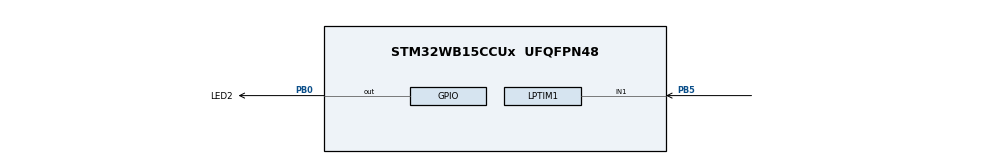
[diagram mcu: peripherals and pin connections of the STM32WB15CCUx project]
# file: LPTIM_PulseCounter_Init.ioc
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LPTIM1.TriggerSource=LPTIM_TRIGSOURCE_SOFTWARE
LPTIM1.ULPClockPolarity=LPTIM_CLOCKPOLARITY_RISING
LPTIM1.ULPClockSampleTime=LPTIM_CLOCKSAMPLETIME_DIRECTTRANSITION
LPTIM1.UpdateMode=LPTIM_UPDATE_IMMEDIATE
Mcu.Family=STM32WB
Mcu.Name=STM32WB15CCUx
Mcu.Package=UFQFPN48
NVIC.LPTIM1_IRQn=true\:0\:0\:false\:false\:true\:true\:true
NVIC.PriorityGroup=NVIC_PRIORITYGROUP_4
PB0.GPIO_Label=LED2
PB0.Signal=GPIO_Output
PB5.GPIO_PuPd=GPIO_PULLDOWN
PB5.GPIO_Speed=GPIO_SPEED_FREQ_HIGH
PB5.Mode=Counts_external_clock_with_synchro_01_occur1
PB5.Signal=LPTIM1_IN1
ProjectManager.HeapSize=0x200
ProjectManager.StackSize=0x400
ProjectManager.TargetToolchain=EWARM V8
RCC.AHB2CLKDivider=RCC_SYSCLK_DIV2
RCC.AHBFreq_Value=64000000
RCC.APB1Freq_Value=64000000
RCC.APB1TimFreq_Value=64000000
RCC.APB2Freq_Value=64000000
RCC.APB2TimFreq_Value=64000000
RCC.APB3Freq_Value=16000000
RCC.CortexFreq_Value=64000000
RCC.HCLKFreq_Value=64000000
RCC.HSE_VALUE=8000000
RCC.HSI_VALUE=16000000
RCC.LPTIM1CLockSelection=RCC_LPTIM1CLKSOURCE_LSI
RCC.LSE_VALUE=32768
RCC.PLLN=32
RCC.SYSCLKFreq_VALUE=64000000
RCC.SYSCLKSource=RCC_SYSCLKSOURCE_PLLCLK
RCC.VCOOutputFreq_Value=128000000
board=custom

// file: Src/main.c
/* USER CODE BEGIN Header */
/**
  ******************************************************************************
  * @file    Examples_LL/LPTIM/LPTIM_PulseCounter_Init/Src/main.c
  * @author  MCD Application Team
  * @brief   This example describes how to use the LPTIM in counter mode
  *          using the STM32WBxx LPTIM LL API.
  *          Peripheral initialization done using LL initialization function.
  ******************************************************************************
  * @attention
  *
  * <h2><center>&copy; Copyright (c) 2019 STMicroelectronics.
  * All rights reserved.</center></h2>
  *
  * This software component is licensed by ST under BSD 3-Clause license,
  * the "License"; You may not use this file except in compliance with the
  * License. You may obtain a copy of the License at:
  *                        opensource.org/licenses/BSD-3-Clause
  *
  ******************************************************************************
  */
/* USER CODE END Header */
#include "main.h"

void SystemClock_Config(void);
static void MX_GPIO_Init(void);
static void MX_LPTIM1_Init(void);
/* USER CODE BEGIN PFP */
void Enable_LSI(void);
void EnterStop1Mode(void);
/* USER CODE END PFP */

int main(void)
{

  /* MCU Configuration--------------------------------------------------------*/

  /* Reset of all peripherals, Initializes the Flash interface and the Systick. */

  NVIC_SetPriorityGrouping(NVIC_PRIORITYGROUP_4);

  /* System interrupt init*/

  /* Configure the system clock */
  SystemClock_Config();

  /* USER CODE BEGIN SysInit */

  /* Enable the LSI Clock */
  Enable_LSI();

  /* USER CODE END SysInit */

  /* Initialize all configured peripherals */
  MX_GPIO_Init();
  MX_LPTIM1_Init();
  /* USER CODE BEGIN 2 */

  /* Enter STOP 1 mode */
  EnterStop1Mode();

  /* USER CODE END 2 */

  /* Infinite loop */
  while (1)
  {

  }
}

void SystemClock_Config(void)
{
  LL_FLASH_SetLatency(LL_FLASH_LATENCY_3);
  while(LL_FLASH_GetLatency() != LL_FLASH_LATENCY_3)
  {
  }

  /* HSI configuration and activation */
  LL_RCC_HSI_Enable();
  while(LL_RCC_HSI_IsReady() != 1)
  {
  }

  LL_RCC_LSI1_Enable();

  /* Wait till LSI is ready */
  while(LL_RCC_LSI1_IsReady() != 1)
  {
  }

  /* MSI configuration and activation */
  LL_RCC_MSI_Enable();
  while(LL_RCC_MSI_IsReady() != 1)
  {
  }

  /* Main PLL configuration and activation */
  LL_RCC_PLL_ConfigDomain_SYS(LL_RCC_PLLSOURCE_MSI, LL_RCC_PLLM_DIV_1, 32, LL_RCC_PLLR_DIV_2);
  LL_RCC_PLL_Enable();
  LL_RCC_PLL_EnableDomain_SYS();
  while(LL_RCC_PLL_IsReady() != 1)
  {
  }

  /* Sysclk activation on the main PLL */
  /* Set CPU1 prescaler*/
  LL_RCC_SetAHBPrescaler(LL_RCC_SYSCLK_DIV_1);

  /* Set CPU2 prescaler*/
  LL_C2_RCC_SetAHBPrescaler(LL_RCC_SYSCLK_DIV_2);

  LL_RCC_SetSysClkSource(LL_RCC_SYS_CLKSOURCE_PLL);
  while(LL_RCC_GetSysClkSource() != LL_RCC_SYS_CLKSOURCE_STATUS_PLL)
  {
  }

  /* Set AHB SHARED prescaler*/
  LL_RCC_SetAHB4Prescaler(LL_RCC_SYSCLK_DIV_1);

  /* Set APB1 prescaler*/
  LL_RCC_SetAPB1Prescaler(LL_RCC_APB1_DIV_1);

  /* Set APB2 prescaler*/
  LL_RCC_SetAPB2Prescaler(LL_RCC_APB2_DIV_1);

  LL_Init1msTick(64000000);

  /* Update CMSIS variable (which can be updated also through SystemCoreClockUpdate function) */
  LL_SetSystemCoreClock(64000000);
  LL_RCC_SetLPTIMClockSource(LL_RCC_LPTIM1_CLKSOURCE_LSI);
  LL_RCC_SetSMPSClockSource(LL_RCC_SMPS_CLKSOURCE_HSI);
  LL_RCC_SetSMPSPrescaler(LL_RCC_SMPS_DIV_1);
  LL_RCC_SetRFWKPClockSource(LL_RCC_RFWKP_CLKSOURCE_NONE);
}

static void MX_LPTIM1_Init(void)
{

  LL_GPIO_InitTypeDef GPIO_InitStruct = {0};

  /* Peripheral clock enable */
  LL_APB1_GRP1_EnableClock(LL_APB1_GRP1_PERIPH_LPTIM1);

  LL_AHB2_GRP1_EnableClock(LL_AHB2_GRP1_PERIPH_GPIOB);
  /**LPTIM1 GPIO Configuration
  PB5   ------> LPTIM1_IN1
  */
  GPIO_InitStruct.Pin = LL_GPIO_PIN_5;
  GPIO_InitStruct.Mode = LL_GPIO_MODE_ALTERNATE;
  GPIO_InitStruct.Speed = LL_GPIO_SPEED_FREQ_HIGH;
  GPIO_InitStruct.OutputType = LL_GPIO_OUTPUT_PUSHPULL;
  GPIO_InitStruct.Pull = LL_GPIO_PULL_DOWN;
  GPIO_InitStruct.Alternate = LL_GPIO_AF_1;
  LL_GPIO_Init(GPIOB, &GPIO_InitStruct);

  /* LPTIM1 interrupt Init */
  NVIC_SetPriority(LPTIM1_IRQn, NVIC_EncodePriority(NVIC_GetPriorityGrouping(),0, 0));
  NVIC_EnableIRQ(LPTIM1_IRQn);

  /* USER CODE BEGIN LPTIM1_Init 1 */

  /* LPTIM1 interrupts set-up */
  /* Enable the Autoreload match Interrupt */
  LL_LPTIM_EnableIT_ARRM(LPTIM1);

  /* USER CODE END LPTIM1_Init 1 */
  LL_LPTIM_SetClockSource(LPTIM1, LL_LPTIM_CLK_SOURCE_INTERNAL);
  LL_LPTIM_SetPrescaler(LPTIM1, LL_LPTIM_PRESCALER_DIV1);
  LL_LPTIM_SetPolarity(LPTIM1, LL_LPTIM_OUTPUT_POLARITY_REGULAR);
  LL_LPTIM_SetUpdateMode(LPTIM1, LL_LPTIM_UPDATE_MODE_IMMEDIATE);
  LL_LPTIM_SetCounterMode(LPTIM1, LL_LPTIM_COUNTER_MODE_EXTERNAL);
  LL_LPTIM_ConfigClock(LPTIM1, LL_LPTIM_CLK_FILTER_NONE, LL_LPTIM_CLK_POLARITY_RISING);
  LL_LPTIM_TrigSw(LPTIM1);
  LL_LPTIM_SetInput1Src(LPTIM1, LL_LPTIM_INPUT1_SRC_GPIO);
  LL_LPTIM_SetInput2Src(LPTIM1, LL_LPTIM_INPUT2_SRC_GPIO);
  /* USER CODE BEGIN LPTIM1_Init 2 */

  /* Enable the LPTIM1 counter */
  LL_LPTIM_Enable(LPTIM1);

  /* Set the Autoreload value */
  LL_LPTIM_SetAutoReload(LPTIM1, 1000);

  /* Start the LPTIM counter in continuous mode */
  LL_LPTIM_StartCounter(LPTIM1, LL_LPTIM_OPERATING_MODE_CONTINUOUS);

  /* USER CODE END LPTIM1_Init 2 */

}

static void MX_GPIO_Init(void)
{
  LL_GPIO_InitTypeDef GPIO_InitStruct = {0};

  /* GPIO Ports Clock Enable */
  LL_AHB2_GRP1_EnableClock(LL_AHB2_GRP1_PERIPH_GPIOB);

  /**/
  LL_GPIO_ResetOutputPin(LED2_GPIO_Port, LED2_Pin);

  /**/
  GPIO_InitStruct.Pin = LED2_Pin;
  GPIO_InitStruct.Mode = LL_GPIO_MODE_OUTPUT;
  GPIO_InitStruct.Speed = LL_GPIO_SPEED_FREQ_LOW;
  GPIO_InitStruct.OutputType = LL_GPIO_OUTPUT_PUSHPULL;
  GPIO_InitStruct.Pull = LL_GPIO_PULL_NO;
  LL_GPIO_Init(LED2_GPIO_Port, &GPIO_InitStruct);

}

/* USER CODE BEGIN 4 */

/**
  * @brief  Enable Internal Low Speed Clock (LSI)
  * @param  None
  * @retval Status
  */
void Enable_LSI(void)
{
  /* Enable LSI Oscillator */
  LL_RCC_LSI1_Enable();

  while(LL_RCC_LSI1_IsReady() != 1)
  {
  };
}

/**
  * @brief  Function to configure and enter in STOP 1 Mode.
  * @param  None
  * @retval None
  */
void EnterStop1Mode(void)
{
  /* Set low-power mode "Stop" */
  LL_PWR_SetPowerMode(LL_PWR_MODE_STOP1);

  /* Set low-power mode "Stop" of CPU2 */
  /* Note: On STM32WB, both CPU1 and CPU2 must be in stop mode to set the entire system in stop mode */
  LL_C2_PWR_SetPowerMode(LL_PWR_MODE_STOP1);
  /* Set SLEEPDEEP bit of Cortex System Control Register */
  LL_LPM_EnableDeepSleep();

  /* Request Wait For Interrupt */
  __WFI();
}

/******************************************************************************/
/*   USER IRQ HANDLER TREATMENT                                               */
/******************************************************************************/
/**
  * @brief  LPTimer Autoreload match interrupt processing
  * @param  None
  * @retval None
  */
void LPTimerAutoreloadMatch_Callback(void)
{
  LL_GPIO_TogglePin(LED2_GPIO_Port, LED2_Pin);
}

/* USER CODE END 4 */

void Error_Handler(void)
{
}

/************************ (C) COPYRIGHT STMicroelectronics *****END OF FILE****/
